AUTOSAR XML (schema 00046)
package /CDD_SWC_1_package
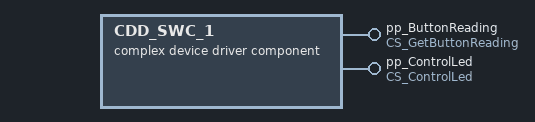
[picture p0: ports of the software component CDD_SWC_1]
  complex device driver sw component type CDD_SWC_1
    provide port pp_ButtonReading: provided-com-specs=[CS_GetButtonReading_Operation_1, CS_GetButtonReading_Operation_2], provided-interface=CS_GetButtonReading
    provide port pp_ControlLed: server-com-spec=CS_ControlLed_Operation_1, provided-interface=CS_ControlLed
    behavior CDD_SWC_1_internal_behavior
      init event Init_Event_1_event: start-on-event=CDD_SWC_1_Init_Runnable
      operation invoked event Operation_Invoked_Event_Read1_event: start-on-event=CDD_SWC_1_Get_Reading_1, operation=pp_ButtonReading.CS_GetButtonReading_Operation_1
      operation invoked event Operation_Invoked_Event_2_event: start-on-event=CDD_SWC_1_Get_Reading_2, operation=pp_ButtonReading.CS_GetButtonReading_Operation_2
      operation invoked event Operation_Invoked_Event_ContolLed_event: start-on-event=CDD_SWC_1_ControlLed, operation=pp_ControlLed.CS_ControlLed_Operation_1
      4 x runnable:
        CDD_SWC_1_Init_Runnable
        CDD_SWC_1_Get_Reading_1
        CDD_SWC_1_Get_Reading_2
        CDD_SWC_1_ControlLed
